AUTOSAR XML (schema 4-0-3)
standard types defined: Boolean, UInt32
package /AUTOSAR_Platform/DataConstrs
  range DC_Boolean: raw 0..1
package /PATAC/MSM/ComponentTypes
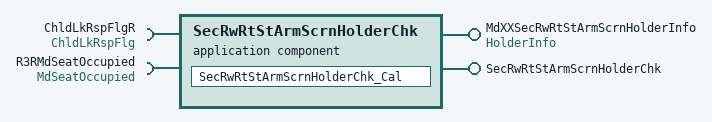
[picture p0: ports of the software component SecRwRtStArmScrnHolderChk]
  application sw component type SecRwRtStArmScrnHolderChk
    provide port MdXXSecRwRtStArmScrnHolderInfo: nonqueued-sender-com-spec{data-element=HolderInfo/Val, init-value=0}, provided-interface=HolderInfo
    provide port SecRwRtStArmScrnHolderChk: server-com-spec{operation=Cal, queue-length=1}, provided-interface=SecRwRtStArmScrnHolderChk
    require port ChldLkRspFlgR: nonqueued-receiver-com-spec{data-element=ChldLkRspFlg/Val, filter=data-filter-type=ALWAYS, init-value=0}, required-interface=ChldLkRspFlg
    require port R3RMdSeatOccupied: nonqueued-receiver-com-spec{data-element=MdSeatOccupied/Val, filter=data-filter-type=ALWAYS, init-value=0}, required-interface=MdSeatOccupied
    behavior SecRwRtStArmScrnHolderChk_InternalBehavior
      operation invoked event OIT_SecRwRtStArmScrnHolderChk_Cal_SecRwRtStArmScrnHolderChk_Cal: start-on-event=SecRwRtStArmScrnHolderChk_Cal, operation=SecRwRtStArmScrnHolderChk.Cal
      runnable SecRwRtStArmScrnHolderChk_Cal
        data-receive-point-by-arguments:
          access REC_ChldLkRspFlgR_Val: accessed-variable=ChldLkRspFlgR.Val
          access REC_R3RMdSeatOccupied_Val: accessed-variable=R3RMdSeatOccupied.Val
        data-send-points:
          access SEND_MdXXSecRwRtStArmScrnHolderInfo_Val: accessed-variable=MdXXSecRwRtStArmScrnHolderInfo.Val
  swc implementation SecRwRtStArmScrnHolderChk_Implementation: behavior=SecRwRtStArmScrnHolderChk_InternalBehavior
    code-descriptors:
      code Default: artifact-descriptors=autosar-engineering-object={short-label=Default, category=SWSRC}
package /PATAC/MSM/ModeAdjust/PortInterface
  client server interface SecRwRtStArmScrnHolderChk
    operation Cal
  sender receiver interface ChldLkRspFlg: invalidation-policy{data-element=ChldLkRspFlg/Val, handle-invalid=DONT-INVALIDATE}
    data Val: type=Boolean
  sender receiver interface HolderInfo: invalidation-policy{data-element=HolderInfo/Val, handle-invalid=DONT-INVALIDATE}
    data Val: type=UInt32
  sender receiver interface MdSeatOccupied: invalidation-policy{data-element=MdSeatOccupied/Val, handle-invalid=DONT-INVALIDATE}
    data Val: type=Boolean
